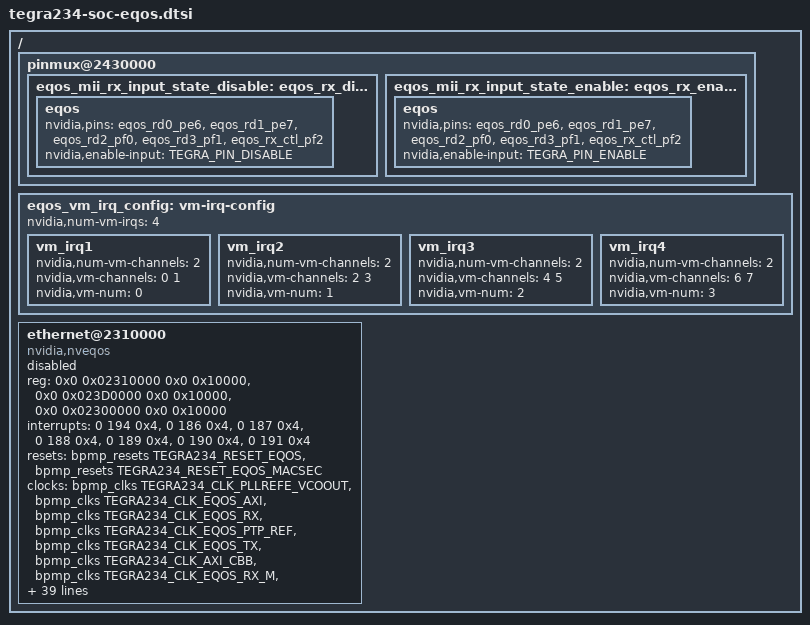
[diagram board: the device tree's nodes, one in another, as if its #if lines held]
/*
 * Copyright (c) 2020-2021, NVIDIA CORPORATION.  All rights reserved.
 *
 * This program is free software; you can redistribute it and/or modify it
 * under the terms and conditions of the GNU General Public License,
 * version 2, as published by the Free Software Foundation.
 *
 * This program is distributed in the hope it will be useful, but WITHOUT
 * ANY WARRANTY; without even the implied warranty of MERCHANTABILITY or
 * FITNESS FOR A PARTICULAR PURPOSE.  See the GNU General Public License for
 * more details.
 *
 * You should have received a copy of the GNU General Public License
 * along with this program.  If not, see <http://www.gnu.org/licenses/>.
 */

/*
 * tegra234-soc-eqos.dtsi: Ethernet QOS DTSI file.
 */

/ {
	pinmux@2430000 {
		eqos_mii_rx_input_state_disable: eqos_rx_disable {
			eqos {
				nvidia,pins = "eqos_rd0_pe6","eqos_rd1_pe7",
						"eqos_rd2_pf0","eqos_rd3_pf1",
						"eqos_rx_ctl_pf2";
				nvidia,enable-input = <TEGRA_PIN_DISABLE>;
			};
		};
		eqos_mii_rx_input_state_enable: eqos_rx_enable {
			eqos {
				nvidia,pins = "eqos_rd0_pe6","eqos_rd1_pe7",
						"eqos_rd2_pf0","eqos_rd3_pf1",
						"eqos_rx_ctl_pf2";
				nvidia,enable-input = <TEGRA_PIN_ENABLE>;
			};
		};
	};

	eqos_vm_irq_config: vm-irq-config {
		nvidia,num-vm-irqs = <4>;
		vm_irq1 {
			nvidia,num-vm-channels = <2>;
			nvidia,vm-channels = <0 1>;
			nvidia,vm-num = <0>;
		};
		vm_irq2 {
			nvidia,num-vm-channels = <2>;
			nvidia,vm-channels = <2 3>;
			nvidia,vm-num = <1>;
		};
		vm_irq3 {
			nvidia,num-vm-channels = <2>;
			nvidia,vm-channels = <4 5>;
			nvidia,vm-num = <2>;
		};
		vm_irq4 {
			nvidia,num-vm-channels = <2>;
			nvidia,vm-channels = <6 7>;
			nvidia,vm-num = <3>;
		};
	};

	ethernet@2310000 {
		compatible = "nvidia,nveqos";
		reg = <0x0 0x02310000 0x0 0x10000>,    /* EQOS Base Register */
		      <0x0 0x023D0000 0x0 0x10000>,    /* MACSEC Base Register */
		      <0x0 0x02300000 0x0 0x10000>;    /* HV Base Register */
		reg-names = "mac", "macsec-base", "hypervisor";
		interrupts = <0 194 0x4>,       /* common */
			     <0 186 0x4>, /* vm0 */
			     <0 187 0x4>, /* vm1 */
			     <0 188 0x4>, /* vm2 */
			     <0 189 0x4>, /* vm3 */
			     <0 190 0x4>, /* MACsec non-secure intr */
			     <0 191 0x4>; /* MACsec secure intr */
		interrupt-names = "common", "vm0", "vm1", "vm2", "vm3",
				  "macsec-ns-irq", "macsec-s-irq";
		resets = <&bpmp_resets TEGRA234_RESET_EQOS>,
			 <&bpmp_resets TEGRA234_RESET_EQOS_MACSEC>; /* MACsec non-secure reset */
		reset-names = "mac", "macsec_ns_rst";
		clocks = <&bpmp_clks TEGRA234_CLK_PLLREFE_VCOOUT>,
			 <&bpmp_clks TEGRA234_CLK_EQOS_AXI>,
			 <&bpmp_clks TEGRA234_CLK_EQOS_RX>,
			 <&bpmp_clks TEGRA234_CLK_EQOS_PTP_REF>,
			 <&bpmp_clks TEGRA234_CLK_EQOS_TX>,
			 <&bpmp_clks TEGRA234_CLK_AXI_CBB>,
			 <&bpmp_clks TEGRA234_CLK_EQOS_RX_M>,
			 <&bpmp_clks TEGRA234_CLK_EQOS_RX_INPUT>,
			 <&bpmp_clks TEGRA234_CLK_EQOS_MACSEC_TX>,
			 <&bpmp_clks TEGRA234_CLK_EQOS_TX_DIVIDER>,
			 <&bpmp_clks TEGRA234_CLK_EQOS_MACSEC_RX>;
		clock-names = "pllrefe_vcoout", "eqos_axi", "eqos_rx",
			      "eqos_ptp_ref", "eqos_tx", "axi_cbb",
			      "eqos_rx_m", "eqos_rx_input",
			      "eqos_macsec_tx", "eqos_tx_divider",
			      "eqos_macsec_rx";
#if TEGRA_IOMMU_DT_VERSION >= DT_VERSION_2
		interconnects = <&mc TEGRA234_MEMORY_CLIENT_EQOSR>,
				<&mc TEGRA234_MEMORY_CLIENT_EQOSW>;
		interconnect-names = "dma-mem", "write";
#endif
		iommus = <&smmu_niso1 TEGRA_SID_NISO1_EQOS>;
		nvidia,num-dma-chans = <8>;
		nvidia,num-mtl-queues = <8>;
		nvidia,mtl-queues = <0 1 2 3 4 5 6 7>;
		nvidia,dma-chans = <0 1 2 3 4 5 6 7>;
		nvidia,tc-mapping = <0 1 2 3 4 5 6 7>;
		/* Residual Queue can be any valid queue except RxQ0 */
		nvidia,residual-queue = <1>;
		nvidia,rx-queue-prio = <0x2 0x1 0x30 0x48 0x0 0x0 0x0 0x0>;
		nvidia,tx-queue-prio = <0x0 0x7 0x2 0x3 0x0 0x0 0x0 0x0>;
		nvidia,rxq_enable_ctrl = <2 2 2 2 2 2 2 2>;
		nvidia,vm-irq-config = <&eqos_vm_irq_config>;
		status = "disabled";
		nvidia,dcs-enable = <0x1>;
		nvidia,pad_calibration = <0x1>;
		nvidia,rx_riwt = <512>;
		nvidia,rx_frames = <64>;
		nvidia,tx_usecs = <256>;
		nvidia,tx_frames = <5>;
		nvidia,promisc_mode = <1>;
		nvidia,slot_num_check = <0x0 0x0 0x0 0x0 0x0 0x0 0x0 0x0>;
		nvidia,slot_intvl_vals = <0x0 0x7D 0x7D 0x7D 0x7D 0x7D 0x7D 0x7D>;
		nvidia,ptp_ref_clock_speed = <208333334>;
		nvidia,instance_id = <4>; /* EQOS instance */
		nvidia,ptp-rx-queue = <3>;
		pinctrl-names = "mii_rx_disable", "mii_rx_enable";
		pinctrl-0 = <&eqos_mii_rx_input_state_disable>;
		pinctrl-1 = <&eqos_mii_rx_input_state_enable>;
		dma-coherent;
		nvidia,dma_rx_ring_sz = <1024>;
		nvidia,dma_tx_ring_sz = <1024>;
	};
};
